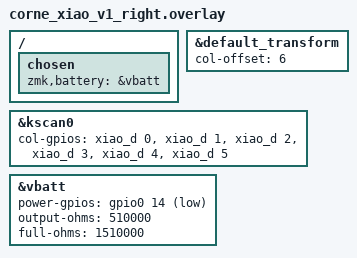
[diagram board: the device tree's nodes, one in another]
#include "corne_xiao_v1.dtsi"

/ {
    chosen {
        zmk,battery = &vbatt;
    };
};

&default_transform {
    col-offset = <6>;
};

&kscan0 {
    /* 標準配線に戻します (D0, D1, D2, D3, D4, D5) */
    col-gpios
        = <&xiao_d 0 GPIO_ACTIVE_HIGH>
        , <&xiao_d 1 GPIO_ACTIVE_HIGH>
        , <&xiao_d 2 GPIO_ACTIVE_HIGH>
        , <&xiao_d 3 GPIO_ACTIVE_HIGH>
        , <&xiao_d 4 GPIO_ACTIVE_HIGH>
        , <&xiao_d 5 GPIO_ACTIVE_HIGH>
        ;
};

&vbatt {
    power-gpios = <&gpio0 14 (GPIO_OPEN_DRAIN | GPIO_ACTIVE_LOW)>;
    /* XIAO nRF52840 の公式分圧値: 上側 1MΩ, 下側 510kΩ */
    output-ohms = <510000>;   // 下側抵抗 510kΩ
    full-ohms = <1510000>;    // 合計 = 1M + 510k (実電圧＝報告電圧)
};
